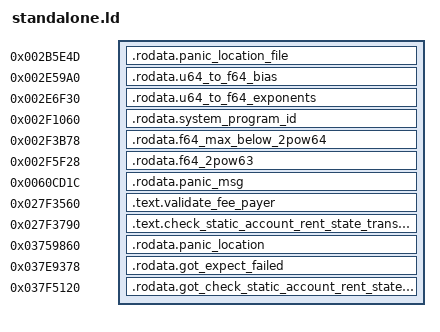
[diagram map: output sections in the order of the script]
/* Generated by vfp-carve. */
ENTRY(validate_fee_payer)

PHDRS
{
  seg0 PT_LOAD FLAGS(4);
  seg1 PT_LOAD FLAGS(4);
  seg2 PT_LOAD FLAGS(4);
  seg3 PT_LOAD FLAGS(4);
  seg4 PT_LOAD FLAGS(4);
  seg5 PT_LOAD FLAGS(4);
  seg6 PT_LOAD FLAGS(4);
  seg7 PT_LOAD FLAGS(5);
  seg8 PT_LOAD FLAGS(5);
  seg9 PT_LOAD FLAGS(4);
  seg10 PT_LOAD FLAGS(4);
  seg11 PT_LOAD FLAGS(4);
}

SECTIONS
{
  .rodata.panic_location_file 0x2b5e4d : { KEEP(*(.rodata.panic_location_file)) } :seg0
  .rodata.u64_to_f64_bias 0x2e59a0 : { KEEP(*(.rodata.u64_to_f64_bias)) } :seg1
  .rodata.u64_to_f64_exponents 0x2e6f30 : { KEEP(*(.rodata.u64_to_f64_exponents)) } :seg2
  .rodata.system_program_id 0x2f1060 : { KEEP(*(.rodata.system_program_id)) } :seg3
  .rodata.f64_max_below_2pow64 0x2f3b78 : { KEEP(*(.rodata.f64_max_below_2pow64)) } :seg4
  .rodata.f64_2pow63 0x2f5f28 : { KEEP(*(.rodata.f64_2pow63)) } :seg5
  .rodata.panic_msg 0x60cd1c : { KEEP(*(.rodata.panic_msg)) } :seg6
  .text.validate_fee_payer 0x27f3560 : { KEEP(*(.text.validate_fee_payer)) } :seg7
  .text.check_static_account_rent_state_transition 0x27f3790 : { KEEP(*(.text.check_static_account_rent_state_transition)) } :seg8
  .rodata.panic_location 0x3759860 : { KEEP(*(.rodata.panic_location)) } :seg9
  .rodata.got_expect_failed 0x37e9378 : { KEEP(*(.rodata.got_expect_failed)) } :seg10
  .rodata.got_check_static_account_rent_state_transition 0x37f5120 : { KEEP(*(.rodata.got_check_static_account_rent_state_transition)) } :seg11
  /DISCARD/ : { *(.note*) *(.comment) *(.eh_frame*) }
}

/* _RNvNtCsgxBkk5gSRhY_4core6option13expect_failed: not carved; reaching it means the function panicked. */
expect_failed = 0x12be100;
